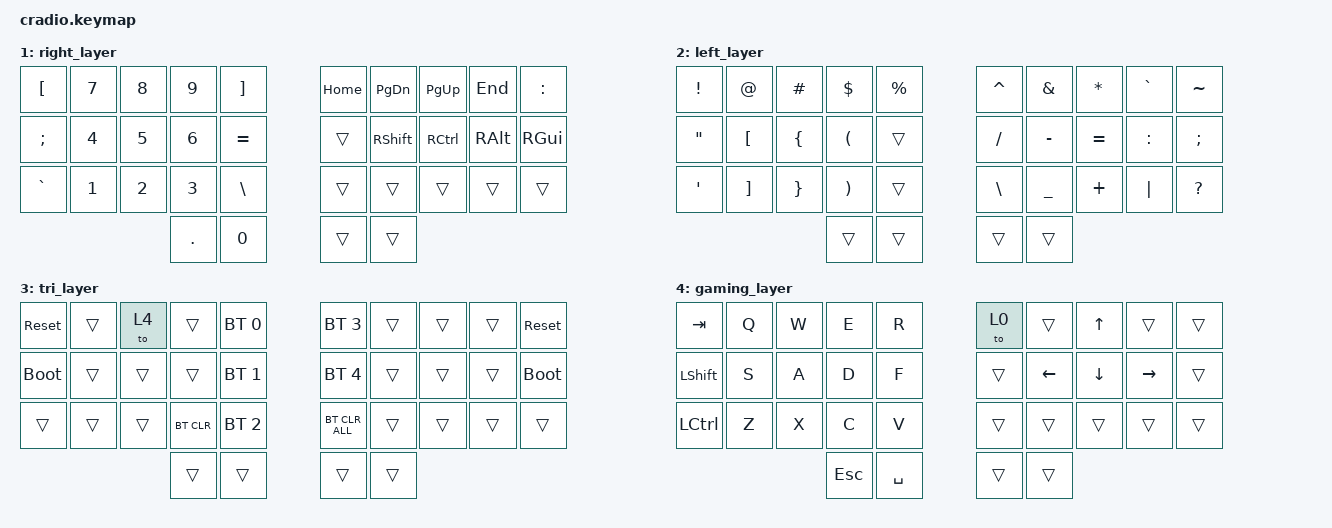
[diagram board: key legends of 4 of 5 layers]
// Copyright (c) 2022 The ZMK Contributors
// SPDX-License-Identifier: MIT

#include <behaviors.dtsi>
#include <dt-bindings/zmk/keys.h>
#include <dt-bindings/zmk/bt.h>

// Home row mods macro
#define HRML(k1,k2,k3,k4) &ht LGUI k1  &ht LALT k2  &ht LCTRL k3  &ht LSHFT k4
#define HRMR(k1,k2,k3,k4) &ht RSHFT k1  &ht RCTRL k2  &ht RALT k3  &ht RGUI k4

/ {
    behaviors {
        ht: hold_tap {
            label = "hold_tap";
            compatible = "zmk,behavior-hold-tap";
            #binding-cells = <2>;
            flavor = "tap-preferred";
            tapping-term-ms = <220>;
            quick-tap-ms = <150>;
            global-quick-tap;
            bindings = <&kp>, <&kp>;
        };
    };

    conditional_layers {
        compatible = "zmk,conditional-layers";
        tri_layer {
            if-layers = <1 2>;
            then-layer = <3>;
        };
    };

    keymap {
        compatible = "zmk,keymap";
        default_layer {
            bindings = <
        //╭──────────┬──────────┬──────────┬──────────┬──────────╮   ╭──────────┬──────────┬──────────┬──────────┬──────────╮
        //│  Q       │  W       │  F       │  P       │  B       │   │  J       │  L       │  U       │  Y       │  '       │
            &kp Q      &kp W      &kp F      &kp P      &kp B          &kp J      &kp L      &kp U      &kp Y      &kp APOS
        //├──────────┼──────────┼──────────┼──────────┼──────────┤   ├──────────┼──────────┼──────────┼──────────┼──────────┤
        //│  A       │  R       │  S       │  T       │  G       │   │  M       │  N       │  E       │  I       │ ' O      │
            HRML(A,        R,         S,         T)     &kp G          &kp M      HRMR(N,        E,         I,        O)
        //├──────────┼──────────┼──────────┼──────────┼──────────┤   ├──────────┼──────────┼──────────┼──────────┼──────────┤
        //│  Z       │  X       │  C       │  D       │  V       │   │  K       │  H       │ , <      │ . >      │ / ?      │
            &kp Z      &kp X      &kp C      &kp D      &kp V          &kp K      &kp H      &kp COMMA  &kp DOT    &kp FSLH
        //╰──────────┴──────────┴──────────┼──────────┼──────────┤   ├──────────┼──────────┼──────────┴──────────┴──────────╯
                                            &lt 2 TAB   &kp ENTER     &kp SPACE  &lt 1 BSPC
        //                                 ╰──────────┴──────────╯   ╰──────────┴──────────╯
            >;
        };

        right_layer {
            bindings = <
        //╭──────────┬──────────┬──────────┬──────────┬──────────╮   ╭──────────┬──────────┬──────────┬──────────┬──────────╮
        //│ INSERT   │  7       │  8       │  9       │          │   │ HOME     │ PAGE DN  │ PAGE UP  │ END      │  :       │
            &kp LBKT    &kp N7     &kp N8     &kp N9     &kp RBKT      &kp HOME   &kp PG_DN  &kp PG_UP  &kp END    &kp COLON
        //├──────────┼──────────┼──────────┼──────────┼──────────┤   ├──────────┼──────────┼──────────┼──────────┼──────────┤
        //│ DELETE   │  4       │  5       │  6       │          │   │ LEFT     │ DOWN     │ UP       │ RIGHT    │  ;       │
            &kp SEMI    &kp N4     &kp N5     &kp N6     &kp EQUAL     &trans    &kp RSHFT  &kp RCTRL   &kp RALT   &kp RGUI
        //├──────────┼──────────┼──────────┼──────────┼──────────┤   ├──────────┼──────────┼──────────┼──────────┼──────────┤
        //│ CAPS     │  1       │  2       │  3       │  0       │   │          │          │          │          │          │
            &kp GRAVE      &kp N1     &kp N2     &kp N3     &kp BSLH      &trans     &trans     &trans     &trans     &trans
        //╰──────────┴──────────┴──────────┼──────────┼──────────┤   ├──────────┼──────────┼──────────┴──────────┴──────────╯
                                             &kp DOT     &kp N0        &trans     &trans
        //                                 ╰──────────┴──────────╯   ╰──────────┴──────────╯
            >;
        };

        left_layer {
            bindings = <
        //╭──────────┬──────────┬──────────┬──────────┬──────────╮   ╭──────────┬──────────┬──────────┬──────────┬──────────╮
        //│  !       │  @       │  #       │  $       │  %       │   │  ^       │  &       │  *       │  `       │  ~       │
            &kp EXCL   &kp AT     &kp HASH   &kp DLLR   &kp PRCNT      &kp CARET  &kp AMPS   &kp ASTRK  &kp GRAVE   &kp TILDE
        //├──────────┼──────────┼──────────┼──────────┼──────────┤   ├──────────┼──────────┼──────────┼──────────┼──────────┤
        //│  "       │  [       │  {       │  (       │          │   │   /      │  -       │  =       │     :    │  ;       │
            &kp DQT  &kp LBKT   &kp LBRC   &kp LPAR   &trans         &kp FSLH   &kp MINUS  &kp EQUAL  &kp COLON   &kp SEMI
        //├──────────┼──────────┼──────────┼──────────┼──────────┤   ├──────────┼──────────┼──────────┼──────────┼──────────┤
        //│  '       │  ]       │  }       │  )       │          │   │    \     │  _       │  +       │  │       │   ?      │
            &kp SQT     &kp RBKT   &kp RBRC   &kp RPAR   &trans         &kp BSLH   &kp UNDER  &kp PLUS   &kp PIPE  &kp QMARK
        //╰──────────┴──────────┴──────────┼──────────┼──────────┤   ├──────────┼──────────┼──────────┴──────────┴──────────╯
                                             &trans     &trans         &trans     &trans
        //                                 ╰──────────┴──────────╯   ╰──────────┴──────────╯
            >;
        };

        tri_layer {
            bindings = <
        //╭──────────┬──────────┬──────────┬──────────┬──────────╮   ╭──────────┬──────────┬──────────┬──────────┬──────────╮
        //│ RESET    │          │to gaming │          │PROFILE 0 │   │ POFILE 3 │          │          │          │  RESET   │
           &sys_reset  &trans     &to 4     &trans    &bt BT_SEL 0    &bt BT_SEL 3 &trans     &trans     &trans    &sys_reset
        //├──────────┼──────────┼──────────┼──────────┼──────────┤   ├──────────┼──────────┼──────────┼──────────┼──────────┤
        //│BOOTLOADER│          │          │          │PROFILE 1 │   │ PROFILE 4│          │          │          │BOOTLOADER│
          &bootloader  &trans     &trans     &trans    &bt BT_SEL 1    &bt BT_SEL 4  &trans     &trans     &trans    &bootloader
        //├──────────┼──────────┼──────────┼──────────┼──────────┤   ├──────────┼──────────┼──────────┼──────────┼──────────┤
        //│          │          │          │ CLEAR BT │PROFILE 2 │   │ CLEAR BTA│          │          │          │          │
            &trans     &trans     &trans    &bt BT_CLR &bt BT_SEL 2    &bt BT_CLR_ALL &trans     &trans     &trans     &trans
        //╰──────────┴──────────┴──────────┼──────────┼──────────┤   ├──────────┼──────────┼──────────┴──────────┴──────────╯
                                             &trans     &trans         &trans     &trans
        //                                 ╰──────────┴──────────╯   ╰──────────┴──────────╯
            >;
        };
        
        gaming_layer {
            bindings = <
        //╭──────────┬──────────┬──────────┬──────────┬──────────╮   ╭──────────┬──────────┬──────────┬──────────┬──────────╮
        //│ TAB      │    Q     │    W     │     E    │     R    │   │ to 0     │          │          │          │  RESET   │
           &kp TAB     &kp Q       &kp W     &kp E       &kp R        &to 0        &trans     &kp UP     &trans    &trans
        //├──────────┼──────────┼──────────┼──────────┼──────────┤   ├──────────┼──────────┼──────────┼──────────┼──────────┤
        //│left shift│    A     │    S     │     D    │     F    │   │ PROFILE 4│          │          │          │BOOTLOADER│
          &kp LSHFT    &kp S     &kp A       &kp D       &kp F        &trans      &kp LEFT   &kp DOWN  &kp RIGHT    &trans
        //├──────────┼──────────┼──────────┼──────────┼──────────┤   ├──────────┼──────────┼──────────┼──────────┼──────────┤
        //│left ctrl │    Z     │    X     │     C    │    V     │   │ CLEAR BTA│          │          │          │          │
            &kp LCTRL    &kp Z     &kp X    &kp C      &kp V          &trans        &trans     &trans     &trans     &trans
        //╰──────────┴──────────┴──────────┼──────────┼──────────┤   ├──────────┼──────────┼──────────┴──────────┴──────────╯
                                             &kp ESC    &kp SPACE       &trans     &trans
        //                                 ╰──────────┴──────────╯   ╰──────────┴──────────╯
            >;
        };
    };
};
